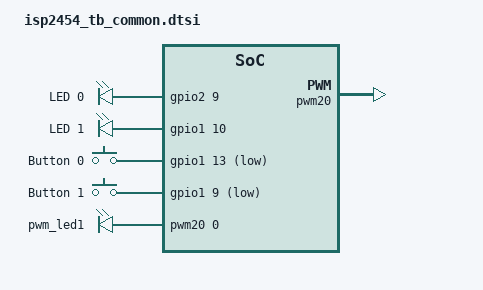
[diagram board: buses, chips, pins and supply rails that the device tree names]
/*
 * Copyright (c) 2026 Ma Compagnie
 * SPDX-License-Identifier: Apache-2.0
 */

/ {
	leds {
		compatible = "gpio-leds";

		led0: led_0 {
			gpios = <&gpio2 9 GPIO_ACTIVE_HIGH>;
			label = "LED 0";
		};
		led1: led_1 {
			gpios = <&gpio1 10 GPIO_ACTIVE_HIGH>;
			label = "LED 1";
		};
	};

	buttons {
		compatible = "gpio-keys";

		button0: button_0 {
			gpios = <&gpio1 13 (GPIO_PULL_UP | GPIO_ACTIVE_LOW)>;
			label = "Button 0";
		};
		button1: button_1 {
			gpios = <&gpio1 9 (GPIO_PULL_UP | GPIO_ACTIVE_LOW)>;
			label = "Button 1";
		};
	};

	pwmleds {
		compatible = "pwm-leds";

		/*
		 * PWM can only drive GPIOs of the same domain: PWM20 works with
		 * port P1 only, so only a LED on P1 (here P1.10) can be dimmed.
		 */
		pwm_led1: pwm_led_1 {
			pwms = <&pwm20 0 PWM_MSEC(20) PWM_POLARITY_NORMAL>;
		};
	};

	aliases {
		led0 = &led0;
		led1 = &led1;
		sw0 = &button0;
		sw1 = &button1;
		pwm-led0 = &pwm_led1;
		mcuboot-led0 = &led0;
		mcuboot-button0 = &button0;
		watchdog0 = &wdt31;
	};
};

&pwm20 {
	status = "okay";
	pinctrl-0 = <&pwm20_default>;
	pinctrl-1 = <&pwm20_sleep>;
	pinctrl-names = "default", "sleep";
};
&spi00 {
	pinctrl-0 = <&spi00_default>;
	pinctrl-1 = <&spi00_sleep>;
	pinctrl-names = "default", "sleep";
	cs-gpios = <&gpio2 5 GPIO_ACTIVE_LOW>;
};
